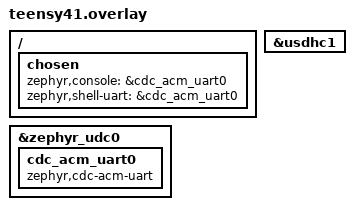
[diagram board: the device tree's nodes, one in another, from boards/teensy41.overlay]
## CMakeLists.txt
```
# Copyright (c) 2026 Ian Adelman
# SPDX-License-Identifier: MIT

cmake_minimum_required(VERSION 3.20.0)

find_package(Zephyr REQUIRED HINTS $ENV{ZEPHYR_BASE})
project(teensy41_tinyllm)

# The inference core is plain C99 shared verbatim with the host build. It is
# compiled straight into the app rather than vendored or wrapped, so there is
# exactly one copy of the numerics and the host tests cover the device.
#
# CONFIGURE_DEPENDS is not decoration: without it CMake expands the glob once
# and caches it, so a newly added core file links fine on the host and fails
# with undefined references here until someone thinks to build pristine.
file(GLOB TQ_CORE_SRC CONFIGURE_DEPENDS
     ${CMAKE_CURRENT_SOURCE_DIR}/../../core/src/*.c)

target_sources(app PRIVATE
    src/main.c
    src/usb_console.c
    src/usb_reboot.c
    src/fault_capture.c
    src/psram_flexspi2.c
    src/model_store.c
    ${TQ_CORE_SRC}
)

target_include_directories(app PRIVATE
    src
    ${CMAKE_CURRENT_SOURCE_DIR}/../../core/include
    ${CMAKE_CURRENT_SOURCE_DIR}/../../core/src
)

# Warnings-as-errors on our own code only. Scoped to `app` rather than set
# globally so Zephyr's own subsystems (which emit deliberate #warnings, e.g.
# CDC-ACM forcing log levels) do not make the build brittle across SDK bumps.
#
# -ffp-contract=off must match host/Makefile exactly. GCC defaults to `fast`,
# which fuses a*b+c into an FMA that rounds once where the unfused pair rounds
# twice. This board is the one target where that matters most: it is the far
# end of a Semaphore decode whose other end is a laptop, and the arithmetic
# decoder desynchronises on a single differing bit. `tinyllm sem hash` must
# print what `tq_sem MODEL.etq hash` prints, and this flag is why it can.
target_compile_options(app PRIVATE -Werror -ffp-contract=off)
```

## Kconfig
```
# Copyright (c) 2026 Ian Adelman
# SPDX-License-Identifier: MIT

mainmenu "Teensy 4.1 Tiny LLM"

config TINYLLM_LOG_LEVEL
	int "Log level for the tinyllm modules"
	default 3
	range 0 4

config TINYLLM_FAST_ARENA_BYTES
	int "Activation arena bytes (OCRAM2)"
	default 262144
	help
	  Holds every activation vector plus the logits. The logits alone are
	  vocab_size * 4 bytes, which is 128 KB for a 32000-token Llama
	  vocabulary, so this dominates. 256 KB comfortably fits a 32k-vocab
	  model with a 1024-token context. Lives in the dedicated 512 KB
	  OCRAM2, which the kernel does not use; DTCM would be faster but is
	  only 128 KB in the default FlexRAM split.

config TINYLLM_STREAM_TILE_BYTES
	int "Bounce buffer for SD-streamed models"
	default 32768
	help
	  Must be at least one full weight-matrix row. SDIO throughput on this
	  slot falls off sharply below 16 KB per read, so do not shrink this
	  below that without measuring.

config TINYLLM_PSRAM_BOOT_CLOCK_INDEX
	int "FlexSPI2 clock index used at boot"
	default 3
	range 0 9
	help
	  Index into the clock table in psram_flexspi2.h. 3 = 105.6 MHz, the
	  same conservative default Teensyduino 1.60 ships. `tinyllm psram
	  sweep` finds the fastest one this board actually tolerates; once you
	  know it, set it here so it applies from boot.

config TINYLLM_PSRAM_MAX_CLOCK_INDEX
	int "Highest clock index the sweep will try"
	default 8
	range 0 9
	help
	  8 = 166.2 MHz. Index 9 (176 MHz) exceeds the datasheet rating of
	  every part PJRC sells and is left out of the default sweep; raise
	  this only if you enjoy debugging intermittent bit flips.

source "Kconfig.zephyr"
```

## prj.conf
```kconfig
# Copyright (c) 2026 Ian Adelman
# SPDX-License-Identifier: MIT
#
# Teensy 4.1 quantized LLM firmware.

CONFIG_MAIN_STACK_SIZE=8192

# ── Console: USB CDC-ACM over the Teensy micro-USB ─────────────────────────
# Same path the board uses for flashing (HalfKay), different USB device once
# Zephyr is up. The 4.x USBD "next" stack is required — the legacy device
# stack is broken on the i.MX RT1062.
CONFIG_SERIAL=y
CONFIG_CONSOLE=y
CONFIG_UART_CONSOLE=y
CONFIG_UART_LINE_CTRL=y
CONFIG_USB_DEVICE_STACK_NEXT=y
CONFIG_USBD_CDC_ACM_CLASS=y
CONFIG_UART_INTERRUPT_DRIVEN=y

# ── Shell ──────────────────────────────────────────────────────────────────
CONFIG_SHELL=y
CONFIG_SHELL_STACK_SIZE=16384
CONFIG_SHELL_CMD_BUFF_SIZE=256
CONFIG_SHELL_PROMPT_UART="tinyllm> "
# The default RX ring buffer is 64 bytes, which silently truncates any
# command longer than that — a `gen` line with a normal sentence prompt is
# ~66 and lost its closing quote, leaving the shell in an unterminated
# string. Must exceed SHELL_CMD_BUFF_SIZE.
CONFIG_SHELL_BACKEND_SERIAL_RX_RING_BUFFER_SIZE=512
CONFIG_SHELL_BACKEND_SERIAL_CHECK_DTR=n

# ── Logging ────────────────────────────────────────────────────────────────
# Deferred, not immediate: immediate mode would block the logging caller on
# USB host backpressure, and a stalled log inside the decode loop turns a
# 600 ms token into an unbounded one.
CONFIG_LOG=y
CONFIG_LOG_MODE_DEFERRED=y
CONFIG_LOG_DEFAULT_LEVEL=3
# The Teensy's SD slot has no card-detect pin, so the driver warns on every
# single read — thousands of lines during a model load.
CONFIG_SDHC_LOG_LEVEL_ERR=y
# The USBD stack logs every control transfer at INFO, which means enumeration
# and any host-side port open scroll dozens of lines through the same console
# the shell is talking on — directly into the middle of command output that
# tools/chat.py and the Semaphore round trip have to parse.
CONFIG_USBD_LOG_LEVEL_ERR=y

# ── Floating point ─────────────────────────────────────────────────────────
# Activations are fp32 and the Cortex-M7 has a real FPU. FPU_SHARING is on
# because the shell thread and the inference run in different threads and both
# touch floats.
CONFIG_FPU=y
CONFIG_FPU_SHARING=y
CONFIG_CBPRINTF_FP_SUPPORT=y

# ── microSD (usdhc1, 4-bit SDIO) — where models live ───────────────────────
CONFIG_DISK_ACCESS=y
CONFIG_DISK_DRIVER_SDMMC=y
CONFIG_SDHC=y
# The v4.0 usdhc driver ADMA2-DMAs into caller buffers with no cache
# maintenance (and its non-DMA fallback cannot even init this slot), so
# every DMA target lives in the .nocache section instead — stage_buf and
# the FATFS sector window in model_store.c. NOCACHE_MEMORY carves that
# MPU region.
CONFIG_NOCACHE_MEMORY=y
CONFIG_SDMMC_STACK=y
CONFIG_FILE_SYSTEM=y
CONFIG_FAT_FILESYSTEM_ELM=y
CONFIG_FS_FATFS_LFN=y
CONFIG_FS_FATFS_MAX_LFN=128
CONFIG_FS_FATFS_EXFAT=y

# ── Heap / stacks ──────────────────────────────────────────────────────────
# The engine never allocates; this is for the SD and USB stacks only.
CONFIG_HEAP_MEM_POOL_SIZE=16384

# ── Faults ─────────────────────────────────────────────────────────────────
# A BusFault on first PSRAM touch is the classic symptom of a bad solder joint.
# EXTRA_EXCEPTION_INFO dumps the full fault registers, making that a
# five-second diagnosis instead of a silent hang. (EXCEPTION_STACK_TRACE
# needs ARCH_STACKWALK, which Cortex-M lacks on Zephyr v4.0.0.)
CONFIG_EXTRA_EXCEPTION_INFO=y
CONFIG_REBOOT=y
```

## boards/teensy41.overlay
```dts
/*
 * Copyright (c) 2026 Ian Adelman
 * SPDX-License-Identifier: MIT
 *
 * Teensy 4.1 overlay.
 *
 * Note what is NOT here: a flexspi2 PSRAM node. Zephyr's upstream teensy41
 * board enables flexspi (the onboard 8 MB program flash) but not flexspi2,
 * and the in-tree APS6404L memc driver does not build for this target on
 * Zephyr 4.0 (zephyr#83244) nor handle two chips or the 16 MB ISSI part.
 * src/psram_flexspi2.c owns that peripheral end to end instead.
 *
 * PSRAM at 0x70000000 is reachable without an MPU region because Zephyr
 * enables PRIVDEFENA on ARMv7-M: privileged accesses fall through to the
 * architectural default map, where 0x60000000-0x9FFFFFFF is Normal, cacheable
 * write-back memory. That is exactly the attribute set we want, and it is why
 * unaligned 32-bit loads of 18-byte Q4 blocks are legal. If CONFIG_USERSPACE
 * is ever turned on, this stops being true and a region has to be declared.
 */

/ {
	chosen {
		zephyr,console = &cdc_acm_uart0;
		zephyr,shell-uart = &cdc_acm_uart0;
	};
};

&zephyr_udc0 {
	cdc_acm_uart0: cdc_acm_uart0 {
		compatible = "zephyr,cdc-acm-uart";
	};
};

/* The native microSD slot. Enabled upstream already; restated here so the
 * dependency is visible at the point of use. */
&usdhc1 {
	status = "okay";
};
```

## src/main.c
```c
/*
 * Copyright (c) 2026 Ian Adelman
 * SPDX-License-Identifier: MIT
 *
 * teensy41-tinyllm — a quantized language model running on a Teensy 4.1.
 *
 * Everything is driven from the Zephyr shell over USB CDC-ACM. The intended
 * first session after soldering is:
 *
 *     tinyllm psram sweep      find the fastest stable FlexSPI2 clock
 *     tinyllm load stories15M.etq
 *     tinyllm gen Once upon a time
 *
 * Memory plan (32 MB PSRAM, 1 MB on-chip):
 *
 *   OCRAM2 activations + logits    ~150 KB   touched thousands of times/token
 *   PSRAM  model weights           8-30 MB   streamed once per token
 *   PSRAM  KV cache                1-9 MB    random access, but small
 *   PSRAB  sampler scratch          256 KB   touched once per token
 *
 * The split is the whole design. Weights get read exactly once per token and
 * never reused, so they belong in the big slow memory; activations get hit
 * constantly, so they belong in the fast one.
 */

#include <stdlib.h>
#include <string.h>

#include <zephyr/kernel.h>
#include <zephyr/logging/log.h>
#include <zephyr/shell/shell.h>

#include "model_store.h"
#include "psram_flexspi2.h"
#include "tq/tq.h"
#include "tq/tq_ac.h"

LOG_MODULE_REGISTER(tinyllm, CONFIG_TINYLLM_LOG_LEVEL);

/* Semaphore wire limits. The 8-bit length field caps a message at 255 tokens;
 * the wire buffer is sized for the pathological case where the model finds the
 * text totally unpredictable and every token costs its full ~16 bits. */
#define SEM_MAX_TOKENS  256
#define SEM_MAX_WIRE    640
#define SEM_HASH_STEPS  8

/* ------------------------------------------------------------------ state */

/* Activations live in OCRAM2, the dedicated 512 KB SRAM the board definition
 * leaves untouched. They cannot go where the original comment claimed:
 * `zephyr,sram` is the 256 KB FlexRAM OCRAM, which must also hold the
 * kernel (a 256 KB arena there overflows the link), and DTCM is only 128 KB
 * in the default FlexRAM split — too small for a 32k-vocab logit buffer
 * alone. Repartitioning FlexRAM to get the hot vectors into single-cycle
 * DTCM is a later, measured optimization; decode is FlexSPI2-bound either
 * way (docs/PERFORMANCE.md). */
static uint8_t fast_arena[CONFIG_TINYLLM_FAST_ARENA_BYTES]
	Z_GENERIC_SECTION(OCRAM2) __aligned(32);
/* 8 at minimum — the parser carves uint64_t structures out of this, which
 * the M7 reads with LDRD. tq_carve compensates for a skewed base now, but a
 * plain uint8_t[] landing on an odd address is worth not relying on. */
static uint8_t model_arena[4096] __aligned(16);
static uint8_t stream_tile[CONFIG_TINYLLM_STREAM_TILE_BYTES]
	Z_GENERIC_SECTION(OCRAM2) __aligned(32);
static char    tok_scratch[64];

static TqStore     g_store;
static TqModel     g_model;
static TqRuntime   g_rt;
static TqTokenizer g_tok;
static bool g_loaded, g_have_tok;
static uint64_t g_model_bytes;
static uint32_t g_kv_off, g_scratch_off;

/* PSRAM allocation cursor, in bytes from PSRAM_BASE. */
static uint32_t psram_alloc(uint32_t *cursor, uint32_t bytes)
{
	uint32_t at = (*cursor + 63u) & ~63u;

	*cursor = at + bytes;
	return at;
}

/* --------------------------------------------------------------- psram cmd */

static int cmd_psram(const struct shell *sh, size_t argc, char **argv)
{
	const struct psram_info *pi;
	const char *sub = (argc > 1) ? argv[1] : "info";

	if (!strcmp(sub, "sweep")) {
		int best = psram_clock_sweep(CONFIG_TINYLLM_PSRAM_MAX_CLOCK_INDEX);

		if (best < 0) {
			shell_error(sh, "no usable clock — check the solder joints "
					"on the eight QSPI pads");
			return -EIO;
		}
		shell_print(sh, "settled at %u.%u MHz",
			    psram_clock_hz(best) / 1000000u,
			    (psram_clock_hz(best) / 100000u) % 10u);
		g_loaded = false;   /* the sweep just scribbled over the array */
		return 0;
	}

	if (!strcmp(sub, "test")) {
		uint32_t mb = psram_info()->mbytes;
		uint32_t bad;

		if (mb == 0u) {
			shell_error(sh, "no PSRAM detected");
			return -ENODEV;
		}
		shell_print(sh, "full memtest over %u MB, this takes a while...", mb);
		bad = psram_memtest(0u, (size_t)mb << 20, false);
		shell_print(sh, "%s (%u bad words)", bad ? "FAIL" : "PASS", bad);
		g_loaded = false;
		return bad ? -EIO : 0;
	}

	if (!strcmp(sub, "bench")) {
		uint32_t r = psram_bench_read(0u, 1024u * 1024u);
		uint32_t w;

		g_loaded = false;
		w = psram_bench_write(0u, 1024u * 1024u);
		shell_print(sh, "sequential read  %u.%02u MB/s",
			    r / 1000u, (r / 10u) % 100u);
		shell_print(sh, "sequential write %u.%02u MB/s",
			    w / 1000u, (w / 10u) % 100u);
		shell_print(sh, "at this read rate a Q4_0 model of N million "
				"parameters decodes at about %u.%02u/N tok/s",
			    (r * 16u) / 9000u, ((r * 16u) / 90u) % 100u);
		return 0;
	}

	pi = psram_info();
	if (pi->mbytes == 0u) {
		shell_print(sh, "no PSRAM detected");
		shell_print(sh, "  chip 1 id: 0x%08x", pi->chip_id[0]);
		shell_print(sh, "  an id of 0x00000000 or 0xffffffff usually "
				"means an open joint on DATA0-3 or SCLK");
		return 0;
	}
	shell_print(sh, "%u MB across %u chip%s @ %u.%u MHz",
		    pi->mbytes, pi->chips, pi->chips == 1 ? "" : "s",
		    pi->clock_hz / 1000000u, (pi->clock_hz / 100000u) % 10u);
	shell_print(sh, "  CS0 (pad EMC_24): %u MB, id 0x%08x",
		    pi->chip_mbytes[0], pi->chip_id[0]);
	shell_print(sh, "  CS1 (pad EMC_22): %u MB, id 0x%08x",
		    pi->chip_mbytes[1], pi->chip_id[1]);
	return 0;
}

/* ---------------------------------------------------------------- loading */

static const struct shell *g_progress_sh;

static void load_progress(uint64_t done, uint64_t total)
{
	static uint32_t last_pct = 0xFFFFFFFFu;
	uint32_t pct = (uint32_t)((done * 100u) / (total ? total : 1u));

	if (pct / 10u != last_pct / 10u) {
		last_pct = pct;
		if (g_progress_sh != NULL) {
			shell_fprintf(g_progress_sh, SHELL_NORMAL, "%u%% ", pct);
		}
	}
}

static int finish_open(const struct shell *sh, int max_seq, int kv8)
{
	uint32_t cursor;
	size_t fast_need, kv_need, scratch_need;
	int rc;

	rc = tq_model_open(&g_model, &g_store, model_arena, sizeof(model_arena));
	if (rc != TQ_OK) {
		shell_error(sh, "model open: %s", tq_strerror(rc));
		return -EINVAL;
	}

	if (max_seq <= 0 || max_seq > g_model.seq_len) {
		max_seq = g_model.seq_len;
	}

	fast_need = tq_runtime_bytes(&g_model, max_seq);
	if (fast_need > sizeof(fast_arena)) {
		shell_error(sh,
			    "activations need %u KB but the arena is %u KB",
			    (unsigned)(fast_need / 1024u),
			    (unsigned)(sizeof(fast_arena) / 1024u));
		shell_error(sh, "shorten the context with -c, or raise "
				"CONFIG_TINYLLM_FAST_ARENA_BYTES and rebuild");
		return -ENOMEM;
	}

	/* Weights already occupy the front of PSRAM when resident; when
	 * streaming they occupy none of it. */
	cursor = (g_store.base != NULL) ? (uint32_t)g_model_bytes : 0u;

	kv_need = tq_kv_bytes(&g_model, max_seq, kv8 ? TQ_KV_Q8 : TQ_KV_F32);
	scratch_need = (size_t)g_model.vocab_size * (sizeof(int32_t) + sizeof(float));

	if (cursor + kv_need + scratch_need > ((uint64_t)psram_info()->mbytes << 20)) {
		shell_error(sh, "KV cache (%u KB) will not fit alongside the "
				"model; try -c %d or --kv8",
			    (unsigned)(kv_need / 1024u), max_seq / 2);
		return -ENOMEM;
	}

	g_kv_off = psram_alloc(&cursor, (uint32_t)kv_need);
	g_scratch_off = psram_alloc(&cursor, (uint32_t)scratch_need);

	rc = tq_runtime_init(&g_rt, &g_model, max_seq,
			     kv8 ? TQ_KV_Q8 : TQ_KV_F32,
			     fast_arena, sizeof(fast_arena),
			     (void *)(uintptr_t)(PSRAM_BASE + g_kv_off), kv_need);
	if (rc != TQ_OK) {
		shell_error(sh, "runtime: %s", tq_strerror(rc));
		return -ENOMEM;
	}

	g_have_tok = (tq_tokenizer_init(&g_tok, &g_model, tok_scratch,
					sizeof(tok_scratch)) == TQ_OK);
	g_loaded = true;

	shell_print(sh, "");
	shell_print(sh, "dim %d  hidden %d  layers %d  heads %d/%d  vocab %d",
		    g_model.dim, g_model.hidden_dim, g_model.n_layers,
		    g_model.n_heads, g_model.n_kv_heads, g_model.vocab_size);
	shell_print(sh, "quant %s  kernel %s  context %d  kv %s%s",
		    g_model.qtype == TQ_DT_Q4_0 ? "q4_0" : "q8_0",
		    tq_kernel_backend(), max_seq, kv8 ? "int8" : "fp32",
		    g_have_tok ? "" : "  (no tokenizer)");
	shell_print(sh, "psram: weights %u KB + kv %u KB + scratch %u KB",
		    (unsigned)(g_model_bytes / 1024u), (unsigned)(kv_need / 1024u),
		    (unsigned)(scratch_need / 1024u));
	shell_print(sh, "arena: activations %u KB of %u KB",
		    (unsigned)(fast_need / 1024u),
		    (unsigned)(sizeof(fast_arena) / 1024u));
	return 0;
}

static void parse_common(size_t argc, char **argv, size_t from,
			 int *max_seq, int *kv8)
{
	size_t i;

	for (i = from; i < argc; i++) {
		if (!strcmp(argv[i], "-c") && i + 1 < argc) {
			*max_seq = atoi(argv[++i]);
		} else if (!strcmp(argv[i], "--kv8")) {
			*kv8 = 1;
		}
	}
}

static int cmd_load(const struct shell *sh, size_t argc, char **argv)
{
	char path[96];
	int max_seq = 0, kv8 = 0;
	int64_t t0;
	int rc;

	if (argc < 2) {
		shell_error(sh, "usage: tinyllm load <file.etq> [-c CTX] [--kv8]");
		return -EINVAL;
	}
	if (psram_info()->mbytes == 0u) {
		shell_error(sh, "no PSRAM — use `tinyllm stream` for SD-resident "
				"models");
		return -ENODEV;
	}
	parse_common(argc, argv, 2, &max_seq, &kv8);

	if (argv[1][0] == '/') {
		strncpy(path, argv[1], sizeof(path) - 1);
	} else {
		snprintk(path, sizeof(path), "/SD:/%s", argv[1]);
	}
	path[sizeof(path) - 1] = '\0';

	g_loaded = false;
	model_close_streaming();

	shell_fprintf(sh, SHELL_NORMAL, "loading %s: ", path);
	g_progress_sh = sh;
	t0 = k_uptime_get();
	rc = model_load_to_psram(path, 0u, &g_store, &g_model_bytes, load_progress);
	g_progress_sh = NULL;
	if (rc != 0) {
		shell_error(sh, "\nload failed: %d", rc);
		return rc;
	}
	{
		int64_t dt = k_uptime_get() - t0;

		shell_print(sh, "done  (%llu KB in %lld ms, %llu KB/s)",
			    (unsigned long long)(g_model_bytes / 1024u), dt,
			    (unsigned long long)(g_model_bytes /
						 (uint64_t)(dt ? dt : 1)));
	}
	return finish_open(sh, max_seq, kv8);
}

static int cmd_stream(const struct shell *sh, size_t argc, char **argv)
{
	char path[96];
	int max_seq = 0, kv8 = 1;   /* streaming implies a big model: default int8 kv */
	int rc;

	if (argc < 2) {
		shell_error(sh, "usage: tinyllm stream <file.etq> [-c CTX]");
		return -EINVAL;
	}
	parse_common(argc, argv, 2, &max_seq, &kv8);

	if (argv[1][0] == '/') {
		strncpy(path, argv[1], sizeof(path) - 1);
	} else {
		snprintk(path, sizeof(path), "/SD:/%s", argv[1]);
	}
	path[sizeof(path) - 1] = '\0';

	g_loaded = false;
	rc = model_open_streaming(path, &g_store, stream_tile,
				  sizeof(stream_tile), &g_model_bytes);
	if (rc != 0) {
		return rc;
	}
	return finish_open(sh, max_seq, kv8);
}

/* ------------------------------------------------------------- generation */

static int cmd_gen(const struct shell *sh, size_t argc, char **argv)
{
	TqSampler sampler;
	int32_t *toks;
	char prompt[192];
	char piece[64];
	int steps = 128, n_prompt, pos, token, next;
	float temp = 0.9f, topp = 0.9f;
	uint32_t seed = 42;
	size_t i, used = 0;
	int64_t t0, t_first = 0;
	uint64_t bytes0;

	if (!g_loaded) {
		shell_error(sh, "no model loaded — `tinyllm load <file.etq>`");
		return -ENODEV;
	}

	prompt[0] = '\0';
	for (i = 1; i < argc; i++) {
		if (!strcmp(argv[i], "-n") && i + 1 < argc) {
			steps = atoi(argv[++i]);
		} else if (!strcmp(argv[i], "-t") && i + 1 < argc) {
			temp = (float)atof(argv[++i]);
		} else if (!strcmp(argv[i], "-p") && i + 1 < argc) {
			topp = (float)atof(argv[++i]);
		} else if (!strcmp(argv[i], "-s") && i + 1 < argc) {
			seed = (uint32_t)strtoul(argv[++i], NULL, 10);
		} else {
			size_t l = strlen(argv[i]);

			if (used + l + 2 < sizeof(prompt)) {
				if (used) {
					prompt[used++] = ' ';
				}
				memcpy(prompt + used, argv[i], l);
				used += l;
				prompt[used] = '\0';
			}
		}
	}

	if (steps > g_rt.max_seq) {
		steps = g_rt.max_seq;
	}

	/* Sampler scratch lives in PSRAM. It is 256 KB at a 32k vocab, which
	 * would be a quarter of DTCM, and it is touched exactly once per
	 * token — the cheapest thing in the whole step to make slow. */
	tq_sampler_init(&sampler, g_model.vocab_size, temp, topp, seed,
			(int32_t *)(uintptr_t)(PSRAM_BASE + g_scratch_off),
			(float *)(uintptr_t)(PSRAM_BASE + g_scratch_off +
					     (uint32_t)g_model.vocab_size * 4u));

	toks = (int32_t *)(uintptr_t)(PSRAM_BASE + g_scratch_off +
				      (uint32_t)g_model.vocab_size * 8u);

	if (g_have_tok) {
		n_prompt = tq_encode(&g_tok, prompt, 1, 0, toks, g_rt.max_seq);
		if (n_prompt < 0) {
			shell_error(sh, "encode: %s", tq_strerror(n_prompt));
			return -EINVAL;
		}
	} else {
		toks[0] = (int32_t)g_model.hdr.bos_token;
		n_prompt = 1;
	}

	bytes0 = g_rt.bytes_read;
	token = (int)toks[0];
	t0 = k_uptime_get();

	for (pos = 0; pos < steps; pos++) {
		int rc = tq_forward(&g_rt, token, pos);

		if (rc != TQ_OK) {
			shell_error(sh, "\nforward at pos %d: %s", pos,
				    tq_strerror(rc));
			return -EIO;
		}
		if (pos == 0) {
			t_first = k_uptime_get() - t0;
		}

		next = (pos + 1 < n_prompt) ? (int)toks[pos + 1]
					    : tq_sample(&sampler, g_rt.logits);
		if (next == (int)g_model.hdr.eos_token) {
			pos++;
			break;
		}
		if (g_have_tok) {
			tq_decode(&g_tok, token, next, piece, sizeof(piece));
			shell_fprintf(sh, SHELL_NORMAL, "%s", piece);
		} else {
			shell_fprintf(sh, SHELL_NORMAL, "%d ", next);
		}
		token = next;
	}

	{
		int64_t dt = k_uptime_get() - t0;
		uint64_t read = g_rt.bytes_read - bytes0;
		uint32_t mtps = (uint32_t)(((uint64_t)pos * 100000u) /
					   (uint64_t)(dt ? dt : 1));   /* tok/s * 100 */
		uint32_t bw = (uint32_t)((read * 1000u) /
					 (uint64_t)(dt ? dt : 1) / 1000u);  /* KB/s */

		shell_print(sh, "\n--");
		shell_print(sh, "%d tokens in %lld ms = %u.%02u tok/s "
				"(first token %lld ms)",
			    pos, dt, mtps / 100u, mtps % 100u, t_first);
		shell_print(sh, "weights read %llu KB total, %llu KB/token, "
				"effective %u.%02u MB/s",
			    (unsigned long long)(read / 1024u),
			    (unsigned long long)(read / 1024u /
						 (uint64_t)(pos ? pos : 1)),
			    bw / 1000u, (bw / 10u) % 100u);
	}
	return 0;
}

/* ------------------------------------------------------------------- info */

static int cmd_info(const struct shell *sh, size_t argc, char **argv)
{
	const struct psram_info *pi = psram_info();

	ARG_UNUSED(argc);
	ARG_UNUSED(argv);

	shell_print(sh, "teensy41-tinyllm");
	shell_print(sh, "  cpu     : %u MHz", (unsigned)(sys_clock_hw_cycles_per_sec() / 1000000u));
	shell_print(sh, "  kernel  : %s", tq_kernel_backend());
	shell_print(sh, "  psram   : %u MB @ %u.%u MHz", pi->mbytes,
		    pi->clock_hz / 1000000u, (pi->clock_hz / 100000u) % 10u);
	shell_print(sh, "  arena   : %u KB ocram2, %u KB stream tile",
		    (unsigned)(sizeof(fast_arena) / 1024u),
		    (unsigned)(sizeof(stream_tile) / 1024u));
	if (g_loaded) {
		shell_print(sh, "  model   : %llu KB, %s, ctx %d",
			    (unsigned long long)(g_model_bytes / 1024u),
			    g_model.qtype == TQ_DT_Q4_0 ? "q4_0" : "q8_0",
			    g_rt.max_seq);
	} else {
		shell_print(sh, "  model   : none loaded");
	}
	return 0;
}

/* -------------------------------------------------------------- semaphore */

/*
 * Compress a message against the model's own predictions and put the residual
 * surprise on the wire. See core/include/tq/tq_ac.h and issue #15.
 *
 * The count tables are ~6.7 KB and belong in OCRAM2 with the other hot state
 * rather than on the shell thread's stack. `sem_toks` likewise: a 255-token
 * message is a kilobyte, and the shell thread has other work to do.
 */
static TqAcModel sem_pm Z_GENERIC_SECTION(OCRAM2) __aligned(8);
static int32_t   sem_toks[SEM_MAX_TOKENS] Z_GENERIC_SECTION(OCRAM2) __aligned(4);
static uint8_t   sem_wire[SEM_MAX_WIRE];

/* Wire format matches host/tq_sem.c exactly: a flat 8-bit token count, then
 * every token after the BOS. An in-band EOS was measured at 25.4 bits — 29% of
 * a short message — because the model has no reason to expect one. */
#define SEM_LEN_FREQ (TQ_AC_TOT / 256u)

static int sem_ready(const struct shell *sh)
{
	if (!g_loaded) {
		shell_error(sh, "no model loaded — `tinyllm load <file.etq>`");
		return -ENODEV;
	}
	if (!g_have_tok) {
		shell_error(sh, "this model has no tokenizer");
		return -ENOTSUP;
	}
	if (tq_ac_model_init(&sem_pm, g_model.vocab_size) != TQ_OK) {
		shell_error(sh, "vocab %d out of range for the coder",
			    g_model.vocab_size);
		return -EINVAL;
	}
	return 0;
}

static int cmd_sem_encode(const struct shell *sh, size_t argc, char **argv)
{
	char     text[192];
	TqAcEnc  e;
	size_t   used = 0, len, i;
	int      n, rc, pos;
	int64_t  t0;

	rc = sem_ready(sh);
	if (rc) {
		return rc;
	}

	text[0] = '\0';
	for (i = 1; i < argc; i++) {
		size_t l = strlen(argv[i]);

		if (used + l + 2 < sizeof(text)) {
			if (used) {
				text[used++] = ' ';
			}
			memcpy(text + used, argv[i], l);
			used += l;
			text[used] = '\0';
		}
	}

	n = tq_encode(&g_tok, text, 1, 0, sem_toks, SEM_MAX_TOKENS);
	if (n < 0) {
		shell_error(sh, "encode: %s", tq_strerror(n));
		return -EINVAL;
	}
	if (n - 1 > 255 || n > g_rt.max_seq) {
		shell_error(sh, "message too long: %d tokens", n - 1);
		return -EMSGSIZE;
	}

	t0 = k_uptime_get();
	tq_ac_enc_init(&e, sem_wire, sizeof(sem_wire));
	tq_ac_enc_sym(&e, (uint32_t)(n - 1) * SEM_LEN_FREQ, SEM_LEN_FREQ,
		      TQ_AC_TOT);

	for (pos = 0; pos + 1 < n; pos++) {
		rc = tq_forward(&g_rt, (int)sem_toks[pos], pos);
		if (rc != TQ_OK) {
			shell_error(sh, "forward %d: %s", pos, tq_strerror(rc));
			return -EIO;
		}
		rc = tq_ac_enc_token(&e, &sem_pm, g_rt.logits, (int)sem_toks[pos + 1]);
		if (rc != TQ_OK) {
			shell_error(sh, "code %d: %s", pos, tq_strerror(rc));
			return -EIO;
		}
	}
	len = tq_ac_enc_finish(&e);
	t0 = k_uptime_get() - t0;

	if (e.overflow) {
		shell_error(sh, "wire buffer overflowed");
		return -ENOBUFS;
	}

	shell_fprintf(sh, SHELL_NORMAL, "wire  : ");
	for (i = 0; i < len; i++) {
		shell_fprintf(sh, SHELL_NORMAL, "%02x", sem_wire[i]);
	}
	shell_fprintf(sh, SHELL_NORMAL, "\n");
	shell_print(sh, "bytes : %u from %u chars (%u.%02u bits/char, %u tokens)",
		    (unsigned)len, (unsigned)used,
		    (unsigned)(len * 8u / (used ? used : 1u)),
		    (unsigned)((len * 800u / (used ? used : 1u)) % 100u),
		    (unsigned)(n - 1));
	shell_print(sh, "time  : %u ms (%d forward passes)",
		    (unsigned)t0, n - 1);
	return 0;
}

static int cmd_sem_decode(const struct shell *sh, size_t argc, char **argv)
{
	TqAcDec  d;
	char     piece[64];
	size_t   len = 0;
	const char *hex = argv[1];
	uint32_t target;
	int      rc, want, n, prev;
	int64_t  t0;

	ARG_UNUSED(argc);

	rc = sem_ready(sh);
	if (rc) {
		return rc;
	}

	len = hex2bin(hex, strlen(hex), sem_wire, sizeof(sem_wire));
	if (len == 0) {
		shell_error(sh, "expected hex wire bytes");
		return -EINVAL;
	}

	t0 = k_uptime_get();
	tq_ac_dec_init(&d, sem_wire, len);
	target = tq_ac_dec_target(&d, TQ_AC_TOT);
	want   = (int)(target / SEM_LEN_FREQ);
	tq_ac_dec_update(&d, (uint32_t)want * SEM_LEN_FREQ, SEM_LEN_FREQ);

	if (want + 1 > SEM_MAX_TOKENS || want + 1 > g_rt.max_seq) {
		shell_error(sh, "decoded length %d is implausible — corrupt wire?",
			    want);
		return -EMSGSIZE;
	}

	sem_toks[0] = (int32_t)g_model.hdr.bos_token;
	for (n = 1; n < want + 1; n++) {
		int next;

		rc = tq_forward(&g_rt, (int)sem_toks[n - 1], n - 1);
		if (rc != TQ_OK) {
			shell_error(sh, "forward %d: %s", n - 1, tq_strerror(rc));
			return -EIO;
		}
		next = tq_ac_dec_token(&d, &sem_pm, g_rt.logits);
		if (next < 0) {
			shell_error(sh, "decode %d: %s", n, tq_strerror(next));
			return -EIO;
		}
		sem_toks[n] = (int32_t)next;
	}
	t0 = k_uptime_get() - t0;

	shell_fprintf(sh, SHELL_NORMAL, "text  : ");
	prev = (int)sem_toks[0];
	for (n = 1; n < want + 1; n++) {
		if (tq_decode(&g_tok, prev, (int)sem_toks[n], piece,
			      sizeof(piece)) >= 0) {
			shell_fprintf(sh, SHELL_NORMAL, "%s", piece);
		}
		prev = (int)sem_toks[n];
	}
	shell_fprintf(sh, SHELL_NORMAL, "\n");
	shell_print(sh, "time  : %u ms (%d forward passes)", (unsigned)t0, want);
	return 0;
}

/*
 * FNV-1a over the raw bytes of the logits, for a fixed token sequence derived
 * from the vocabulary size so it needs no tokenizer and works on any model.
 *
 * This is the load-bearing check for Semaphore: `tq_sem MODEL.etq hash` on the
 * host must print the identical value. If it does, this board and that laptop
 * compute byte-identical probability tables and can be the two ends of one
 * arithmetic-coded message. If it does not, no amount of protocol work will
 * make them interoperate. See core/include/tq/tq_math.h.
 */
static int cmd_sem_hash(const struct shell *sh, size_t argc, char **argv)
{
	uint64_t h = 1469598103934665603ull;
	int      step, i, k, rc;
	int64_t  t0;

	ARG_UNUSED(argc);
	ARG_UNUSED(argv);

	if (!g_loaded) {
		shell_error(sh, "no model loaded");
		return -ENODEV;
	}

	t0 = k_uptime_get();
	for (step = 0; step < SEM_HASH_STEPS; step++) {
		int tok = (step * 4099 + 17) % g_model.vocab_size;

		rc = tq_forward(&g_rt, tok, step);
		if (rc != TQ_OK) {
			shell_error(sh, "forward %d: %s", step, tq_strerror(rc));
			return -EIO;
		}
		for (i = 0; i < g_model.vocab_size; i++) {
			uint8_t b[sizeof(float)];

			memcpy(b, &g_rt.logits[i], sizeof(b));
			for (k = 0; k < (int)sizeof(b); k++) {
				h ^= (uint64_t)b[k];
				h *= 1099511628211ull;
			}
		}
	}
	t0 = k_uptime_get() - t0;

	shell_print(sh, "logit bit hash: %08x%08x  [%s]",
		    (unsigned)(h >> 32), (unsigned)(h & 0xFFFFFFFFu),
		    tq_kernel_backend());
	shell_print(sh, "  %d steps in %u ms — compare with "
			"`tq_sem MODEL.etq hash`", SEM_HASH_STEPS, (unsigned)t0);
	return 0;
}

SHELL_STATIC_SUBCMD_SET_CREATE(sem_cmds,
	SHELL_CMD_ARG(encode, NULL, "encode <text...> — compress to wire bytes",
		      cmd_sem_encode, 2, 24),
	SHELL_CMD_ARG(decode, NULL, "decode <hex> — recover the message",
		      cmd_sem_decode, 2, 0),
	SHELL_CMD_ARG(hash,   NULL, "hash — logit fingerprint, must match the host",
		      cmd_sem_hash, 1, 0),
	SHELL_SUBCMD_SET_END
);

SHELL_STATIC_SUBCMD_SET_CREATE(tinyllm_cmds,
	SHELL_CMD_ARG(psram,  NULL,
		      "psram [info|sweep|test|bench]", cmd_psram, 1, 1),
	SHELL_CMD_ARG(load,   NULL,
		      "load <file.etq> [-c CTX] [--kv8]  — copy into PSRAM",
		      cmd_load, 2, 4),
	SHELL_CMD_ARG(stream, NULL,
		      "stream <file.etq> [-c CTX]  — run from SD, no PSRAM copy",
		      cmd_stream, 2, 4),
	SHELL_CMD_ARG(gen,    NULL,
		      "gen [-n N] [-t T] [-p P] [-s SEED] <prompt...>",
		      cmd_gen, 1, 24),
	SHELL_CMD_ARG(info,   NULL, "show configuration", cmd_info, 1, 0),
	SHELL_CMD(sem, &sem_cmds,
		  "compress a message against the model itself", NULL),
	SHELL_SUBCMD_SET_END
);
SHELL_CMD_REGISTER(tinyllm, &tinyllm_cmds, "Tiny LLM on Teensy 4.1", NULL);

int main(void)
{
	int mb;

	LOG_INF("teensy41-tinyllm starting");

	/*
	 * Bring PSRAM up at the conservative clock. `tinyllm psram sweep` will
	 * push it as fast as this particular pair of chips and this particular
	 * solder job can go — that is a per-board property, not a per-design
	 * one, so it is not safe to assume at boot.
	 */
	mb = psram_init(CONFIG_TINYLLM_PSRAM_BOOT_CLOCK_INDEX);
	if (mb <= 0) {
		LOG_WRN("no PSRAM found — SD streaming still works");
	}

	if (model_sd_mount() != 0) {
		LOG_WRN("no SD card mounted; insert one and re-run "
			"`tinyllm load`");
	}

	LOG_INF("ready — try `tinyllm info`");
	return 0;
}
```

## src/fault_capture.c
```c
/*
 * Copyright (c) 2026 Ian Adelman
 * SPDX-License-Identifier: MIT
 *
 * Fault capture across a reboot.
 *
 * The only console on this board is USB CDC, and USB dies with the CPU: a
 * fault handler's output never reaches the host, so every crash looks like
 * a silent hang. Instead of printing, the handler stashes the register
 * state in a __noinit struct — SRAM survives a warm reset — and resets.
 * The next boot finds the magic and prints the crash that just happened.
 *
 * `tinyllm fault` re-prints the last capture; `tinyllm fault clear` forgets
 * it.
 */

#include <string.h>

#include <zephyr/arch/cpu.h>
#include <zephyr/fatal.h>
#include <zephyr/init.h>
#include <zephyr/kernel.h>
#include <zephyr/logging/log.h>
#include <zephyr/shell/shell.h>
#include <zephyr/sys/barrier.h>
#include <zephyr/sys/reboot.h>

LOG_MODULE_REGISTER(fault, CONFIG_TINYLLM_LOG_LEVEL);

#define FAULT_MAGIC 0x0FA17EDu

struct fault_record {
	uint32_t magic;
	uint32_t reason;
	uint32_t pc;
	uint32_t lr;
	uint32_t psr;
	uint32_t cfsr;    /* configurable fault status: which fault, and why */
	uint32_t hfsr;
	uint32_t bfar;    /* faulting data address, if BFARVALID            */
	uint32_t mmfar;
};

static __noinit struct fault_record last_fault;

void k_sys_fatal_error_handler(unsigned int reason, const struct arch_esf *esf)
{
	last_fault.magic  = FAULT_MAGIC;
	last_fault.reason = reason;
	last_fault.pc     = esf ? esf->basic.pc : 0u;
	last_fault.lr     = esf ? esf->basic.lr : 0u;
	last_fault.psr    = esf ? esf->basic.xpsr : 0u;
	last_fault.cfsr   = SCB->CFSR;
	last_fault.hfsr   = SCB->HFSR;
	last_fault.bfar   = SCB->BFAR;
	last_fault.mmfar  = SCB->MMFAR;

	/* Push the record out of the cache before the reset drops it. */
	barrier_dsync_fence_full();
	sys_reboot(SYS_REBOOT_WARM);
	CODE_UNREACHABLE;
}

static void fault_print(const struct shell *sh)
{
	uint32_t cfsr;

	if (last_fault.magic != FAULT_MAGIC) {
		shell_print(sh, "no fault recorded");
		return;
	}
	cfsr = last_fault.cfsr;
	shell_print(sh, "last fault: reason %u  pc 0x%08x  lr 0x%08x  psr 0x%08x",
		    last_fault.reason, last_fault.pc, last_fault.lr,
		    last_fault.psr);
	shell_print(sh, "  cfsr 0x%08x  hfsr 0x%08x  bfar 0x%08x  mmfar 0x%08x",
		    cfsr, last_fault.hfsr, last_fault.bfar, last_fault.mmfar);
	/* Decode the bits that actually distinguish our failure modes. */
	if (cfsr & (1u << 16)) {
		shell_print(sh, "  UNDEFINSTR — executed garbage");
	}
	if (cfsr & (1u << 24)) {
		shell_print(sh, "  UNALIGNED — unaligned access with STRICT_ALIGN");
	}
	if (cfsr & (1u << 25)) {
		shell_print(sh, "  DIVBYZERO");
	}
	if (cfsr & (1u << 8)) {
		shell_print(sh, "  IBUSERR — instruction fetch failed");
	}
	if (cfsr & (1u << 9)) {
		shell_print(sh, "  PRECISERR — bus error, address in BFAR");
	}
	if (cfsr & (1u << 10)) {
		shell_print(sh, "  IMPRECISERR — late bus error (buffered write)");
	}
	if (cfsr & (1u << 1)) {
		shell_print(sh, "  DACCVIOL — MPU denied a data access, addr in MMFAR");
	}
	if (cfsr & (1u << 0)) {
		shell_print(sh, "  IACCVIOL — MPU denied an instruction fetch");
	}
}

static int cmd_fault(const struct shell *sh, size_t argc, char **argv)
{
	if (argc > 1 && !strcmp(argv[1], "clear")) {
		last_fault.magic = 0u;
		shell_print(sh, "cleared");
		return 0;
	}
	fault_print(sh);
	return 0;
}

SHELL_CMD_REGISTER(fault, NULL, "show the fault that caused the last reboot",
		   cmd_fault);

static int fault_announce(void)
{
	if (last_fault.magic == FAULT_MAGIC) {
		LOG_ERR("rebooted by a fault: pc 0x%08x cfsr 0x%08x "
			"(run `fault` for detail)",
			last_fault.pc, last_fault.cfsr);
	}
	return 0;
}

SYS_INIT(fault_announce, APPLICATION, CONFIG_APPLICATION_INIT_PRIORITY);
```

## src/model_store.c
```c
/*
 * Copyright (c) 2026 Ian Adelman
 * SPDX-License-Identifier: MIT
 */

#include <string.h>

#include <zephyr/fs/fs.h>
#include <zephyr/kernel.h>
#include <zephyr/logging/log.h>
#include <zephyr/storage/disk_access.h>
#include <ff.h>

#include "model_store.h"
#include "psram_flexspi2.h"

LOG_MODULE_REGISTER(model_store, CONFIG_TINYLLM_LOG_LEVEL);

#define SD_MOUNT "/SD:"

/* Everything the USDHC ADMA engine writes must be non-cacheable: the v4.0
 * driver does no cache maintenance on data buffers, so a cacheable target
 * serves stale lines to the CPU afterwards (this corrupted the first real
 * model image in transit). That covers the staging buffer below and FATFS
 * itself — its embedded sector window is the DMA target for all metadata
 * and small/unaligned reads. */
static FATFS fat_fs __nocache;
static struct fs_mount_t mp = {
	.type = FS_FATFS,
	.fs_data = &fat_fs,
	.mnt_point = SD_MOUNT,
};
static bool mounted;

/*
 * 32 KB. SDIO throughput on the Teensy's slot collapses below about 16 KB per
 * read (per-block command overhead dominates) and stops improving much above
 * 32 KB. This buffer is also the streaming tile, so it has to be at least one
 * full matrix row: 32 KB covers a 4096-wide Q8_0 row with room to spare.
 */
#define STAGE_BYTES (32u * 1024u)
static uint8_t stage_buf[STAGE_BYTES] __nocache __aligned(32);

int model_sd_mount(void)
{
	static const char *disk = "SD";

	/* The .nocache section is NOLOAD — never zeroed at boot — so the
	 * FATFS struct starts as stack garbage unless cleared here. */
	if (!mounted) {
		memset(&fat_fs, 0, sizeof(fat_fs));
	}
	uint32_t block_count = 0, block_size = 0;
	int rc;

	if (mounted) {
		return 0;
	}

	rc = disk_access_init(disk);
	if (rc != 0) {
		LOG_ERR("no SD card (disk_access_init=%d) — card seated? "
			"FAT32/exFAT formatted?", rc);
		return rc;
	}
	(void)disk_access_ioctl(disk, DISK_IOCTL_GET_SECTOR_COUNT, &block_count);
	(void)disk_access_ioctl(disk, DISK_IOCTL_GET_SECTOR_SIZE, &block_size);

	rc = fs_mount(&mp);
	if (rc != 0) {
		LOG_ERR("fs_mount: %d", rc);
		return rc;
	}
	mounted = true;
	LOG_INF("SD mounted at %s (%u MB)", SD_MOUNT,
		(unsigned)(((uint64_t)block_count * block_size) >> 20));
	return 0;
}

static int open_sized(const char *path, struct fs_file_t *f, uint64_t *size)
{
	struct fs_dirent ent;
	int rc;

	rc = fs_stat(path, &ent);
	if (rc != 0) {
		LOG_ERR("stat %s: %d", path, rc);
		return rc;
	}
	*size = ent.size;

	fs_file_t_init(f);
	rc = fs_open(f, path, FS_O_READ);
	if (rc != 0) {
		LOG_ERR("open %s: %d", path, rc);
		return rc;
	}
	return 0;
}

int model_load_to_psram(const char *path, uint32_t psram_off, TqStore *store,
			uint64_t *out_bytes,
			void (*progress)(uint64_t done, uint64_t total))
{
	struct fs_file_t f;
	uint64_t size = 0, done = 0;
	uint8_t *dst;
	const struct psram_info *pi = psram_info();
	int rc;

	rc = model_sd_mount();
	if (rc != 0) {
		return rc;
	}
	rc = open_sized(path, &f, &size);
	if (rc != 0) {
		return rc;
	}

	if (pi->mbytes == 0u) {
		LOG_ERR("no PSRAM detected — use `tinyllm stream` instead");
		fs_close(&f);
		return -ENODEV;
	}
	if (psram_off + size > ((uint64_t)pi->mbytes << 20)) {
		LOG_ERR("model is %llu MB but only %u MB of PSRAM is fitted; "
			"stream it from the card instead",
			(unsigned long long)(size >> 20), pi->mbytes);
		fs_close(&f);
		return -ENOSPC;
	}

	dst = (uint8_t *)(uintptr_t)(PSRAM_BASE + psram_off);
	while (done < size) {
		uint32_t want = (uint32_t)MIN((uint64_t)STAGE_BYTES, size - done);
		ssize_t got = fs_read(&f, stage_buf, want);

		if (got <= 0) {
			LOG_ERR("read at %llu: %d", (unsigned long long)done, (int)got);
			fs_close(&f);
			return (got == 0) ? -EIO : (int)got;
		}
		memcpy(dst + done, stage_buf, (size_t)got);
		done += (uint64_t)got;
		if (progress != NULL) {
			progress(done, size);
		}
	}
	fs_close(&f);

	tq_store_init_mapped(store, dst, size);
	if (out_bytes != NULL) {
		*out_bytes = size;
	}
	LOG_INF("loaded %s: %llu bytes into PSRAM+0x%x",
		path, (unsigned long long)size, psram_off);
	return 0;
}

/* --------------------------------------------------------------- streaming */

static struct fs_file_t stream_file;
static bool stream_open;
static struct k_mutex stream_lock;

static int stream_read(void *ctx, uint64_t off, void *dst, uint32_t nbytes)
{
	uint32_t done = 0;
	int rc = 0;

	ARG_UNUSED(ctx);
	if (!stream_open) {
		return -EBADF;
	}

	k_mutex_lock(&stream_lock, K_FOREVER);
	if (fs_seek(&stream_file, (off_t)off, FS_SEEK_SET) != 0) {
		rc = -EIO;
	}
	/* Bounce through the non-cacheable staging buffer: the engine hands
	 * this callback arbitrary (cacheable) destinations, which must never
	 * be DMA targets — see the note above fat_fs. */
	while (rc == 0 && done < nbytes) {
		uint32_t want = MIN(STAGE_BYTES, nbytes - done);
		ssize_t got = fs_read(&stream_file, stage_buf, want);

		if (got <= 0) {
			rc = -EIO;
			break;
		}
		memcpy((uint8_t *)dst + done, stage_buf, (size_t)got);
		done += (uint32_t)got;
	}
	k_mutex_unlock(&stream_lock);
	return rc;
}

int model_open_streaming(const char *path, TqStore *store, uint8_t *tile,
			 uint32_t tile_bytes, uint64_t *out_bytes)
{
	uint64_t size = 0;
	int rc;

	rc = model_sd_mount();
	if (rc != 0) {
		return rc;
	}
	model_close_streaming();
	k_mutex_init(&stream_lock);

	rc = open_sized(path, &stream_file, &size);
	if (rc != 0) {
		return rc;
	}
	stream_open = true;

	tq_store_init_stream(store, size, stream_read, NULL, tile, tile_bytes);
	if (out_bytes != NULL) {
		*out_bytes = size;
	}
	LOG_INF("streaming %s: %llu bytes, %u KB tile",
		path, (unsigned long long)size, tile_bytes / 1024u);
	LOG_WRN("streaming mode: the tokenizer needs random access and is "
		"unavailable; generation emits raw token ids");
	return 0;
}

void model_close_streaming(void)
{
	if (stream_open) {
		fs_close(&stream_file);
		stream_open = false;
	}
}
```

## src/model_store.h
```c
/*
 * Copyright (c) 2026 Ian Adelman
 * SPDX-License-Identifier: MIT
 *
 * Getting a model from the microSD card into somewhere the engine can read it.
 */

#ifndef MODEL_STORE_H_
#define MODEL_STORE_H_

#include <stddef.h>
#include <stdint.h>

#include "tq/tq.h"

/* Mount the Teensy's native microSD slot (usdhc1, 4-bit SDIO) at /SD:. */
int model_sd_mount(void);

/*
 * Copy `path` into PSRAM at `psram_off` and point `store` at it.
 *
 * The copy goes through a DTCM staging buffer rather than reading straight
 * into PSRAM: the SD stack DMAs into the destination, and PSRAM is a
 * cacheable AHB region, so a direct read would leave the D-cache holding
 * stale lines over freshly DMA'd data. Staging in DTCM and doing a CPU memcpy
 * keeps the cache coherent with no explicit maintenance, and costs nothing
 * measurable next to the SD read itself.
 *
 * Reports progress through `progress` (may be NULL).
 */
int model_load_to_psram(const char *path, uint32_t psram_off, TqStore *store,
			uint64_t *out_bytes,
			void (*progress)(uint64_t done, uint64_t total));

/*
 * Leave the model on the card and stream it.
 *
 * The only way to run a model bigger than the PSRAM fitted. Roughly half the
 * token rate of the resident path, but it is the difference between running a
 * 62 MB model on a 32 MB board and not running it.
 */
int model_open_streaming(const char *path, TqStore *store, uint8_t *tile,
			 uint32_t tile_bytes, uint64_t *out_bytes);

/* Release whatever the streaming store has open. */
void model_close_streaming(void);

#endif /* MODEL_STORE_H_ */
```

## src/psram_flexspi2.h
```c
/*
 * Copyright (c) 2026 Ian Adelman
 * SPDX-License-Identifier: MIT
 *
 * FlexSPI2 PSRAM driver for the Teensy 4.1 bottom-side QSPI pads.
 */

#ifndef PSRAM_FLEXSPI2_H_
#define PSRAM_FLEXSPI2_H_

#include <stdbool.h>
#include <stddef.h>
#include <stdint.h>

/* FlexSPI2 AHB window. Both chip selects map here back to back, so two 16 MB
 * parts appear as one flat 32 MB span. */
#define PSRAM_BASE 0x70000000u

/* Clock options, in the order psram_clock_hz()/psram_init() index them.
 * Derived from the FlexSPI2 PODF/CLK_SEL table in the RT1062 reference manual
 * (CCM_CBCMR). The enum names carry PJRC's NOMINAL labels; rows sourced from
 * a PLL PFD run at whatever fraction the OS programmed (Zephyr's differ from
 * PJRC's), so psram_clock_hz() computes the real value from the CCM_ANALOG
 * registers at runtime. Index 3 (105.6 MHz, PLL2-based and therefore exact)
 * is what Teensyduino 1.60 ships as default. */
enum {
	PSRAM_CLK_88   = 0,
	PSRAM_CLK_99   = 1,
	PSRAM_CLK_103  = 2,
	PSRAM_CLK_106  = 3,
	PSRAM_CLK_111  = 4,
	PSRAM_CLK_120  = 5,
	PSRAM_CLK_132  = 6,
	PSRAM_CLK_144  = 7,
	PSRAM_CLK_166  = 8,
	PSRAM_CLK_176  = 9,
	PSRAM_CLK_COUNT
};

struct psram_info {
	uint8_t  chips;          /* 0, 1 or 2 parts detected           */
	uint32_t mbytes;         /* total capacity                     */
	uint32_t chip_mbytes[2];
	uint32_t chip_id[2];     /* raw JEDEC ID words                 */
	uint32_t clock_hz;
	uint8_t  clock_index;
};

uint32_t psram_clock_hz(int index);

/*
 * Bring up FlexSPI2 and detect what is soldered on.
 *
 * Returns total megabytes (0 if nothing answers). Safe to call repeatedly —
 * `psram sweep` re-runs it at each clock.
 */
int psram_init(int clock_index);

const struct psram_info *psram_info(void);

/* Non-destructive read bandwidth in KB/s over `bytes` starting at `off`. */
uint32_t psram_bench_read(uint32_t off, size_t bytes);

/* Write-then-read bandwidth in KB/s. DESTROYS the region under test. */
uint32_t psram_bench_write(uint32_t off, size_t bytes);

/*
 * Memory test. Destroys the region. Returns 0 on success, or the number of
 * failing words. `quick` samples one word per 4 KB page instead of every word,
 * which is what the clock sweep uses so it does not take a minute per step.
 */
uint32_t psram_memtest(uint32_t off, size_t bytes, bool quick);

/*
 * Walk the clock table upward, memtesting at each step, and leave the part
 * configured at the fastest clock that passes. Returns the chosen index.
 *
 * This is the point of the whole exercise: token rate is proportional to PSRAM
 * bandwidth, and the difference between the 88 MHz default and a part that
 * happens to be stable at 166 MHz is roughly a 1.9x speedup for free.
 */
int psram_clock_sweep(int max_index);

#endif /* PSRAM_FLEXSPI2_H_ */
```

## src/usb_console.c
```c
/*
 * Copyright (c) 2026 Ian Adelman
 * SPDX-License-Identifier: MIT
 *
 * USB CDC-ACM console bring-up for the USBD "next" stack.
 *
 * The chosen zephyr,console / zephyr,shell-uart nodes point at cdc_acm_uart0
 * (boards/teensy41.overlay), but unlike the legacy stack, the next stack
 * instantiates nothing on its own: the application must define the device
 * context, attach descriptors and configurations, and enable it. This file
 * is that boilerplate, run once at APPLICATION init so the console is live
 * before main() starts. SHELL_BACKEND_SERIAL_CHECK_DTR=n in prj.conf keeps
 * boot from blocking when no host terminal is attached.
 */

#include <zephyr/device.h>
#include <zephyr/init.h>
#include <zephyr/logging/log.h>
#include <zephyr/usb/usbd.h>

LOG_MODULE_REGISTER(usb_console, CONFIG_TINYLLM_LOG_LEVEL);

/* pid.codes test allocation — the Zephyr project VID is reserved for
 * upstream samples, and squatting PJRC's would misidentify the board. */
#define TINYLLM_USB_VID 0x1209
#define TINYLLM_USB_PID 0x0001

USBD_DEVICE_DEFINE(tinyllm_usbd, DEVICE_DT_GET(DT_NODELABEL(zephyr_udc0)),
		   TINYLLM_USB_VID, TINYLLM_USB_PID);

USBD_DESC_LANG_DEFINE(tinyllm_lang);
USBD_DESC_MANUFACTURER_DEFINE(tinyllm_mfr, "teensytinyllm");
USBD_DESC_PRODUCT_DEFINE(tinyllm_product, "Teensy 4.1 tinyllm console");
USBD_DESC_SERIAL_NUMBER_DEFINE(tinyllm_sn);
USBD_DESC_CONFIG_DEFINE(tinyllm_fs_desc, "FS Configuration");
USBD_DESC_CONFIG_DEFINE(tinyllm_hs_desc, "HS Configuration");

/* Bus powered; bMaxPower 250 × 2 mA = 500 mA covers the board plus SD and
 * both PSRAM chips with margin. */
USBD_CONFIGURATION_DEFINE(tinyllm_fs_config, 0, 250, &tinyllm_fs_desc);
USBD_CONFIGURATION_DEFINE(tinyllm_hs_config, 0, 250, &tinyllm_hs_desc);

static int add_speed(enum usbd_speed speed, struct usbd_config_node *cfg)
{
	int err;

	err = usbd_add_configuration(&tinyllm_usbd, speed, cfg);
	if (err) {
		return err;
	}
	err = usbd_register_all_classes(&tinyllm_usbd, speed, 1);
	if (err) {
		return err;
	}
	/* CDC-ACM is a multi-interface function: the IAD code triple tells
	 * the host to read class info per interface. */
	usbd_device_set_code_triple(&tinyllm_usbd, speed,
				    USB_BCC_MISCELLANEOUS, 0x02, 0x01);
	return 0;
}

static int usb_console_enable(void)
{
	struct usbd_desc_node *descs[] = {
		&tinyllm_lang, &tinyllm_mfr, &tinyllm_product, &tinyllm_sn,
	};
	unsigned int i;
	int err;

	for (i = 0; i < ARRAY_SIZE(descs); i++) {
		err = usbd_add_descriptor(&tinyllm_usbd, descs[i]);
		if (err) {
			LOG_ERR("descriptor %u: %d", i, err);
			return err;
		}
	}

	/* The RT1062's EHCI controller is high-speed; register both speeds
	 * so a FS-only hub still gets a working console. */
	if (usbd_caps_speed(&tinyllm_usbd) == USBD_SPEED_HS) {
		err = add_speed(USBD_SPEED_HS, &tinyllm_hs_config);
		if (err) {
			LOG_ERR("HS config: %d", err);
			return err;
		}
	}
	err = add_speed(USBD_SPEED_FS, &tinyllm_fs_config);
	if (err) {
		LOG_ERR("FS config: %d", err);
		return err;
	}

	err = usbd_init(&tinyllm_usbd);
	if (err) {
		LOG_ERR("usbd_init: %d", err);
		return err;
	}
	err = usbd_enable(&tinyllm_usbd);
	if (err) {
		LOG_ERR("usbd_enable: %d", err);
		return err;
	}
	return 0;
}

SYS_INIT(usb_console_enable, APPLICATION, CONFIG_APPLICATION_INIT_PRIORITY);
```
